# ATA5787 device description
Architecture: AVR8; Family: megaAVR
Registers are 8-bit, access not given, no defined reset value unless marked. A register's access mark holds for its fields unless they carry their own. Offsets are from the block's base; [hi:lo] are bit positions; 'fields as' and 'values as' point back to an identical list.

## CPU
Instances: CPU 0x00
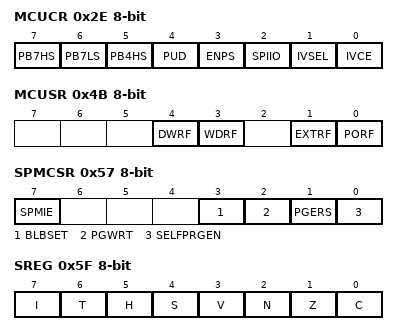
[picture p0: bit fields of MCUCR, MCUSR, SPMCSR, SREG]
0x2E MCUCR — MCU Control Register
  [7] PB7HS — Port B7 High Side Driver Enable
  [6] PB7LS — Port B7 Low Side Driver Enable
  [5] PB4HS — Port B4 High Side Driver Enable
  [4] PUD — Pull-up Resistors Disable
  [3] ENPS — Enable Port Settings
  [2] SPIIO — SPI Interrupt Only
  [1] IVSEL — Interrupt Vector Select
  [0] IVCE — Interrupt Vector Change Enable
0x4B MCUSR — MCU Status Register
  [4] DWRF — DebugWire Reset Flag
  [3] WDRF — Watchdog Reset Flag
  [1] EXTRF — External Reset Flag
  [0] PORF — Power-On Reset Flag
0x51 DWDR — Debug Wire Data Register
0x57 SPMCSR — Store Program Memory Control and Status Register
  [7] SPMIE — SPM Interrupt Enable
  [3] BLBSET — Boot Lock Bit Set
  [2] PGWRT — Page Write
  [1] PGERS — Page Erase
  [0] SELFPRGEN — Self Programming Enable
0x5D SP 16-bit bits used 10:0 — Stack Pointer
0x5F SREG — Status Register
  [7] I — Global Interrupt Enable
  [6] T — Bit Copy Storage
  [5] H — Half Carry Flag
  [4] S — Sign Bit
  [3] V — Two's Complement Overflow Flag
  [2] N — Negative Flag
  [1] Z — Zero Flag
  [0] C — Carry Flag

## CRC
Instances: CRC 0x00
0x49 CRCDIR — CRC Data Input Register
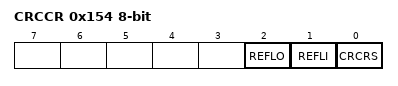
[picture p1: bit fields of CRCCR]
0x154 CRCCR — CRC Control Register
  [2] REFLO — Reflect Data Output Byte
  [1] REFLI — Reflect Data Input Byte
  [0] CRCRS — CRC Data Register Reset
0x155 CRCDOR — CRC Data Output Register

## DEMOD
Instances: DEMOD 0x00
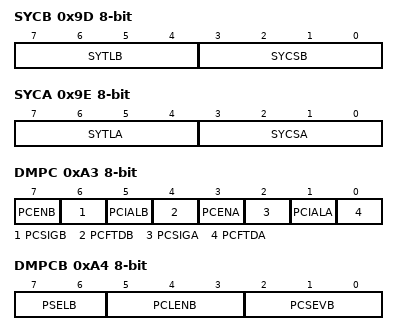
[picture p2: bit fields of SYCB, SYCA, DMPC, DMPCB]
0x9D SYCB — Symbol Check Configuration Path B
  [7:4] SYTLB — Symbol Timing Limit Path B
  [3:0] SYCSB — Symbol Check Size Path B
0x9E SYCA — Symbol Check Configuration Path A
  [7:4] SYTLA — Symbol Timing Limit Path A
  [3:0] SYCSA — Symbol Check Size Path A
0x9F RXFOB — Received Frequency Offset vs Intermediate Frequency Path B
0xA0 RXFOA — Received Frequency Offset vs Intermediate Frequency Path A
0xA1 DMPATB — Demodulator Signal Check Pattern Path B
0xA2 DMPATA — Demodulator Signal Check Pattern Path A
0xA3 DMPC — Demodulator Pattern Check Control
  [7] PCENB — Pattern Check Enable Path B
  [6] PCSIGB — Pattern Check Signal Path B
  [5] PCIALB — Pattern Check Ignore Amplitude Low Path B
  [4] PCFTDB — Pattern Check Frequency Tracking Disable Path B
  [3] PCENA — Pattern Check Enable Path A
  [2] PCSIGA — Pattern Check Signal Path A
  [1] PCIALA — Pattern Check Ignore Amplitude Low Path A
  [0] PCFTDA — Pattern Check Frequency Tracking Disable Path A
0xA4 DMPCB — Demodulator Pattern Check Control Path B
  [7:6] PSELB — Pattern Select Path B
    0=1T_ALTERNATING_0X55_0XAA; 1=2T_ALTERNATING_0X33_0XCC; 2=DMPATX_DEFINED; 3=MANCHESTER_CONFORMAL
  [5:3] PCLENB — Pattern Check Length Path B
  [2:0] PCSEVB — Pattern Check Severity Path B
    0=12_5_PERCENT; 1=25_PERCENT; 2=37_5_PERCENT; 3=50_PERCENT; 4=62_5_PERCENT; 5=75_PERCENT; 6=87_5_PERCENT; 7=100_PERCENT
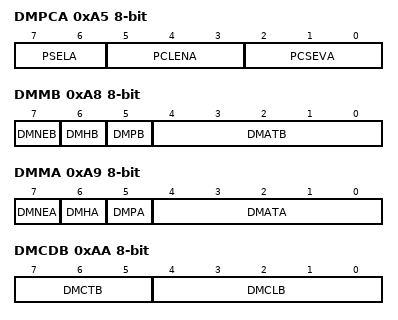
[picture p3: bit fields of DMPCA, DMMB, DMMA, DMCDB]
0xA5 DMPCA — Demodulator Pattern Check Control Path A
  [7:6] PSELA — Pattern Select Path A
    values as DMPCB.PSELB
  [5:3] PCLENA — Pattern Check Length Path A
  [2:0] PCSEVA — Pattern Check Severity Path A
    values as DMPCB.PCSEVB
0xA6 DMSRB — Demodulator Symbol Rate Path B
0xA7 DMSRA — Demodulator Symbol Rate Path A
0xA8 DMMB — Demodulator Mode Path B
  [7] DMNEB — Demodulator NRZ Enable Path B
  [6] DMHB — Demodulator Hold Mode Path B
  [5] DMPB — Demodulator Data Polarity Path B
  [4:0] DMATB — Demodulator Amplitude Threshold Path B
0xA9 DMMA — Demodulator Mode Path A
  [7] DMNEA — Demodulator NRZ Enable Path A
  [6] DMHA — Demodulator Hold Mode Path A
  [5] DMPA — Demodulator Data Polarity Path A
  [4:0] DMATA — Demodulator Amplitude Threshold Path A
0xAA DMCDB — Demodulator Carrier Detect Path B
  [7:5] DMCTB — Demodulator Carrier Detect Time Path B
  [4:0] DMCLB — Demodulator Carrier Detect Limit Path B
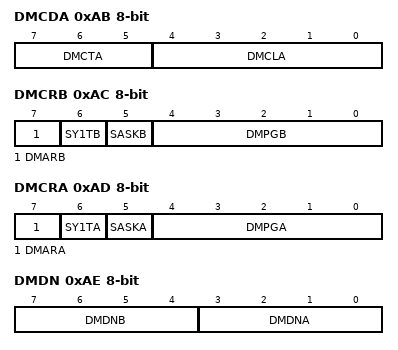
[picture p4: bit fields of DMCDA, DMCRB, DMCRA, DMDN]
0xAB DMCDA — Demodulator Carrier Detect Path A
  [7:5] DMCTA — Demodulator Carrier Detect Time Path A
  [4:0] DMCLA — Demodulator Carrier Detect Limit Path A
0xAC DMCRB — Demodulator Control Path B
  [7] DMARB — Demodulator Automatic Restart Path B
  [6] SY1TB — Symbol Check with only 1T Path B
  [5] SASKB — Select ASK Demodulation Path B
  [4:0] DMPGB — Demodulator PLL Loop Gain Path B
0xAD DMCRA — Demodulator Control Path A
  [7] DMARA — Demodulator Automatic Restart Path A
  [6] SY1TA — Symbol Check with only 1T Path A
  [5] SASKA — Select ASK Demodulation Path A
  [4:0] DMPGA — Demodulator PLL Loop Gain Path A
0xAE DMDN — Demodulator Down Sampling
  [7:4] DMDNB — Demodulator Down-sampling Path B
  [3:0] DMDNA — Demodulator Down-sampling Path A
